# ESP32S31_RADIO register map
Vendor: Espressif; Series: ESP32-S31; File version: 3.52
Registers are 32-bit, read-write, no defined reset value unless marked. A register's access mark holds for its fields unless they carry their own. Offsets are from the block's base; [hi:lo] are bit positions.

## PHY_COLD_DEADLINE_ORACLE — Free-running word sampled by the complete rev0 ROM SDM-stability deadline. The instruction body proves its address and unsigned wraparound consumer, but not its hardware clock source.
Base 0x2010D800
0x00 DEADLINE_COUNTER_UNKNOWN ro — Complete phy_wait_i2c_sdm_stable samples this full word before and after each independently completed PHY-I2C read.
  [31:0] VALUE — Full-width wrapping deadline value.

## PHY_CLOCK_ORACLE — OPAQUE PHY clock-gate registers recovered from complete no-call ROM/blob leaves.
Base 0x20100000
0x400 FE_CLOCK_GATE_OPAQUE wo — ROM writes 0x1e7 to open and the blob writes zero to close.
  [31:0] STATE — Complete observed front-end clock-gate images; constituent gate meanings remain unknown.
    on write: 0=CLOSED; 0x1E7=OPEN
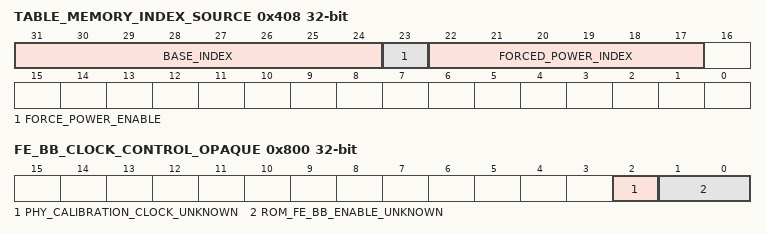
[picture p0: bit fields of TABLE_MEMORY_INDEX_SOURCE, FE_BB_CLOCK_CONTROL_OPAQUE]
0x408 TABLE_MEMORY_INDEX_SOURCE — Shared word contains the table-memory base index and the complete phy_force_pwr_index controls.
  [31:24] BASE_INDEX — Eight-bit table-memory base index; the complete front-end initializer writes 0xa0.
  [23] FORCE_POWER_ENABLE — Complete phy_force_pwr_index replaces bit 23 with the low bit of its first argument.
  [22:17] FORCED_POWER_INDEX — Complete phy_force_pwr_index replaces bits 22:17 with the low six bits of its second argument.
0x800 FE_BB_CLOCK_CONTROL_OPAQUE — ROM sets bits 1:0 and the blob clears them.
  [2] PHY_CALIBRATION_CLOCK_UNKNOWN — The phy_bb_init parent sets bit 2 before calibration; the individual hardware meaning remains unknown.
  [1:0] ROM_FE_BB_ENABLE_UNKNOWN — Two-bit open/close mask; individual meanings are unknown.
    on write: 0=CLOSED; 3=OPEN
0x7C80 BB_CLOCK_GATE_OPAQUE wo — ROM writes all ones to open and the blob writes zero to close.
  [31:0] STATE — Complete observed baseband clock-gate images; constituent gate meanings remain unknown.
    on write: 0=CLOSED; 0xFFFFFFFF=OPEN

## PMU_RADIO — Route-owned PMU words used by the reviewed shared radio clock, RF-power and analog-I2C lifecycles. Unrelated PMU words remain platform-owned.
Base 0x20704000
0x14 HP_ACTIVE_ICG_MODEM reset 0x0 — Active-state modem clock-gating selection.
  [31:30] HP_ACTIVE_DIG_ICG_MODEM_CODE — Two-bit active-state modem clock-gating code; official ESP-HAL publishes code two for the active configuration.
    2=ACTIVE (Active-state modem clock-gating code published by official ESP-HAL.)
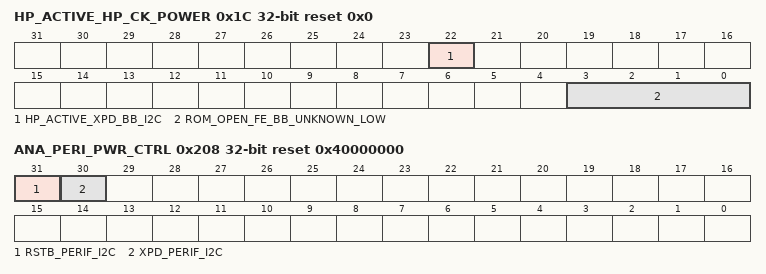
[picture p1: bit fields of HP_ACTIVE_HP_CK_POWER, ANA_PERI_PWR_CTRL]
0x1C HP_ACTIVE_HP_CK_POWER reset 0x0 — Active-state high-power clock and analog-I2C power control reached by the complete front-end/baseband clock body.
  [22] HP_ACTIVE_XPD_BB_I2C — Active-state baseband analog-I2C power control.
  [3:0] ROM_OPEN_FE_BB_UNKNOWN_LOW — Low-nibble image set by complete rev0 ROM phy_open_fe_bb_clk; individual bit semantics remain unknown.
    on write: 15=ROM_REQUIRED (Complete low-nibble image published by the rev0 ROM front-end/baseband clock leaf.)
0xF0 IMM_HP_CK_POWER_0 reset 0x0 — Immediate high-power clock ties. The reviewed complete PHY body reads this word before its preserving update, overriding the write-only access class in the uncorrected public SVD.
  [28] TIE_HIGH_XPD_BB_I2C — Force the baseband analog-I2C power control high.
0xF8 IMM_SLEEP_SYSCLK wo reset 0x0 — Immediate sleep/system-clock update commands.
  [28] UPDATE_DIG_ICG_SWITCH — Publish the selected digital clock-gating switch state.
0x104 IMM_MODEM_ICG wo reset 0x0 — Immediate modem clock-gating update command.
  [31] UPDATE_DIG_ICG_MODEM_EN — Publish the selected digital modem clock-gating state.
0x184 RF_PWC reset 0x0 — RF circuit power control.
  [31:16] XPD_RF_CIRCUIT — Sixteen RF circuit power-control bits.
    0=POWERED_OFF (Clear every reviewed RF circuit power-control bit.); 0xFFFF=POWERED_ON (Set every reviewed RF circuit power-control bit.)
0x208 ANA_PERI_PWR_CTRL reset 0x40000000 — Analog peripheral I2C power and active-low reset control.
  [31] RSTB_PERIF_I2C — Analog peripheral I2C active-low reset release.
  [30] XPD_PERIF_I2C — Analog peripheral I2C power control.
